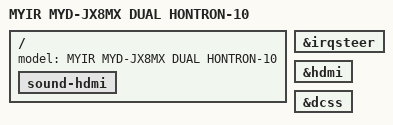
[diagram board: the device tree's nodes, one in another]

#include "myd-jx8mx-lcdif-hontron-7.dts"

/ {
	model = "MYIR MYD-JX8MX DUAL  HONTRON-10";
	sound-hdmi {
		status = "okay";
	};
};

&irqsteer {
	status = "okay";
};

&hdmi {
	status = "okay";
};

&dcss {
	status = "okay";
};
